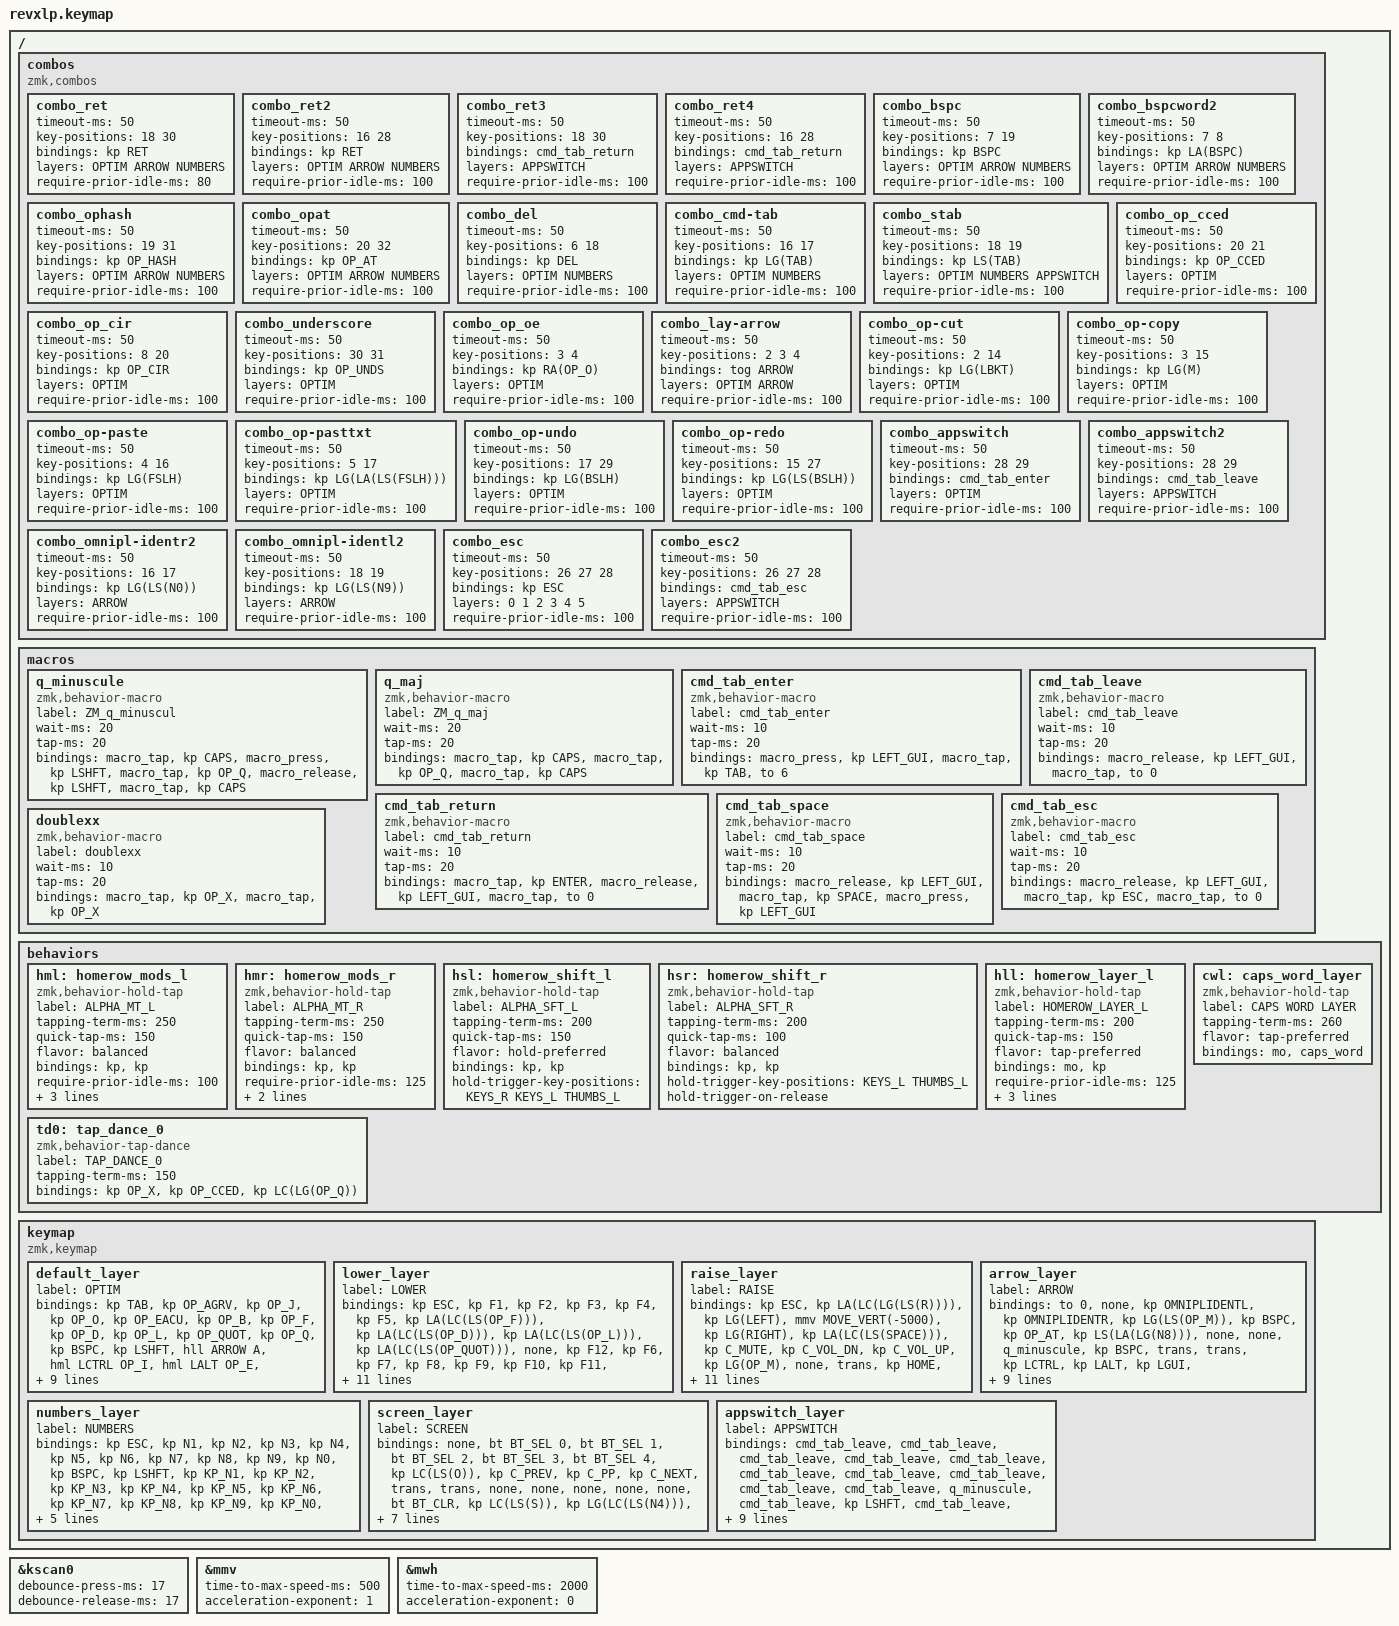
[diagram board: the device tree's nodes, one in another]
/*
 * Copyright (c) 2020 The ZMK Contributors
 *
 * SPDX-License-Identifier: MIT
 */

#include <behaviors.dtsi>
#include <dt-bindings/zmk/keys.h>
#include <dt-bindings/zmk/bt.h>
#include <dt-bindings/zmk/backlight.h>
#include <dt-bindings/zmk/mouse.h>
//#include "keymap_optimot.h"

/*
 * ┌───┬───┬───┬───┬───┬───┬───┬───┬───┬───┬───┬───┬───┬───────┐
 * │ $ │ « │ » │ " │ - │ + │ * │ / │ = │ ( │ ) │ @ │ # │       │
 * ├───┴─┬─┴─┬─┴─┬─┴─┬─┴─┬─┴─┬─┴─┬─┴─┬─┴─┬─┴─┬─┴─┬─┴─┬─┴─┬─────┤
 * │     │ À │ J │ O │ É │ B │ F │ D │ L │ ' │ Q │ X │ Ç │     │
 * ├─────┴┬──┴┬──┴┬──┴┬──┴┬──┴┬──┴┬──┴┬──┴┬──┴┬──┴┬──┴┬──┴┐    │
 * │      │ A │ I │ E │ U │ , │ P │ T │ S │ R │ N │ ^ │ Z │    │
 * ├────┬─┴─┬─┴─┬─┴─┬─┴─┬─┴─┬─┴─┬─┴─┬─┴─┬─┴─┬─┴─┬─┴─┬─┴───┴────┤
 * │    │ K │ Y │ È │ . │ W │   │ G │ C │ M │ H │ V │          │
 * ├────┼───┴┬──┴─┬─┴───┴───┴───┴───┴───┴──┬┴───┼───┴┬────┬────┤
 * │    │    │    │                        │    │    │    │    │
 * └────┴────┴────┴────────────────────────┴────┴────┴────┴────┘
 */
// Row 1
#define OP_DLR  GRAVE // $
#define OP_LDAQ N1    // «
#define OP_RDAQ N2    // »
#define OP_DQUO N3    // "
#define OP_MIN  N4    // -
#define OP_PLUS N5    // +
#define OP_ASTR N6    // *
#define OP_SLSH N7    // /
#define OP_EQL  N8    // =
#define OP_LPRN N9    // (
#define OP_RPRN N0    // )
#define OP_AT   MINUS // @
#define OP_HASH EQUAL // #
// Row 2
#define OP_AGRV Q     // À
#define OP_J    W     // J
#define OP_O    E     // O
#define OP_EACU R     // É
#define OP_B    T     // B
#define OP_F    Y     // F
#define OP_D    U     // D
#define OP_L    I     // L
#define OP_QUOT O     // '
#define OP_Q    P     // Q
#define OP_X    LBKT  // X
#define OP_CCED RBKT  // Ç
// Row 3
#define OP_A    A     // A
#define OP_I    S     // I
#define OP_E    D     // E
#define OP_U    F     // U
#define OP_COMM G     // ,
#define OP_P    H     // P
#define OP_T    J     // T
#define OP_S    K     // S
#define OP_R    L     // R
#define OP_N    SEMI  // N
#define OP_CIR  SQT   // ^
#define OP_Z    BSLH  // Z
// Row 4
#define OP_K    Z     // K
#define OP_Y    X     // Y
#define OP_EGRV C     // È
#define OP_DOT  V     // .
#define OP_W    B     // W
#define OP_G    N     // G
#define OP_C    M     // C
#define OP_M    COMMA // M
#define OP_H    DOT   // H
#define OP_V    FSLH  // V

/* Shifted symbols
 * ┌───┬───┬───┬───┬───┬───┬───┬───┬───┬───┬───┬───┬───┬───────┐
 * │ € │ 1 │ 2 │ 3 │ 4 │ 5 │ 6 │ 7 │ 8 │ 9 │ 0 │ _ │ % │       │
 * ├───┴─┬─┴─┬─┴─┬─┴─┬─┴─┬─┴─┬─┴─┬─┴─┬─┴─┬─┴─┬─┴─┬─┴─┬─┴─┬─────┤
 * │     │   │   │   │   │   │   │   │   │ ? │   │   │   │     │
 * ├─────┴┬──┴┬──┴┬──┴┬──┴┬──┴┬──┴┬──┴┬──┴┬──┴┬──┴┬──┴┬──┴┐    │
 * │      │   │   │   │   │ ; │   │   │   │   │   │ ! │   │    │
 * ├────┬─┴─┬─┴─┬─┴─┬─┴─┬─┴─┬─┴─┬─┴─┬─┴─┬─┴─┬─┴─┬─┴─┬─┴───┴────┤
 * │    │   │   │   │   │ : │   │   │   │   │   │   │          │
 * ├────┼───┴┬──┴─┬─┴───┴───┴───┴───┴───┴──┬┴───┼───┴┬────┬────┤
 * │    │    │    │                        │    │    │    │    │
 * └────┴────┴────┴────────────────────────┴────┴────┴────┴────┘
 */
// Row 1
#define OP_EURO  LS(OP_DLR)  // €
#define OP_1     LS(OP_LDAQ) // 1
#define OP_2     LS(OP_RDAQ) // 2
#define OP_3     LS(OP_DQUO) // 3
#define OP_4     LS(OP_MIN)  // 4
#define OP_5     LS(OP_PLUS) // 5
#define OP_6     LS(OP_ASTR) // 6
#define OP_7     LS(OP_SLSH) // 7
#define OP_8     LS(OP_EQL)  // 8
#define OP_9     LS(OP_LPRN) // 9
#define OP_0     LS(OP_RPRN) // 0
#define OP_UNDS  LS(OP_AT)   // _
#define OP_DEGRE LA(OP_HASH) // º
// Added since this is useful
#define OP_PERC  LS(OP_HASH) // %
// Row 2
#define OP_QUES LS(OP_QUOT)  // ?
// Row 3
#define OP_SCLN LS(OP_COMM)  // ;
// Row 4
#define OP_COLN LS(OP_DOT)   // :
// Row 5
#define OP_NBSP LS(SPACE)   //   (non-breaking space) /!\ Pour la disposition Optimot 1.4 ou 1.5 non altérée, il faut utiler le code LA(SPACE)


//Applications shorcuts
//Omniplan
#define OMNIPLIDENTR LG(LS(N0))
#define OMNIPLIDENTL LG(LS(N9))


#define OPTIM   0
#define LOWER   1
#define RAISE   2
#define ARROW   3
#define NUMBERS 4
#define SCREEN  5
#define APPSWITCH 6

#define CLIPB_HIST LG(LA(OP_P))

/*                KEY POSITIONS

  ╭────────────────────────╮ ╭────────────────────────╮
  │  0   1   2   3   4   5 │ │  6   7   8   9  10  11 │
  │ 12  13  14  15  16  17 │ │ 18  19  20  21  22  23 │
  │ 24  25  26  27  28  29 │ │ 30  31  32  33  34  35 │
  ╰──────────╮  36  37  38 │ │ 39  40  41 ╭───────────╯
             ╰─────────────╯ ╰────────────╯            */

/ {
combos {
    compatible = "zmk,combos";
    combo_ret {
        timeout-ms = <50>;
        key-positions = <18 30>;
        bindings = <&kp RET>;
        layers = <OPTIM ARROW NUMBERS>;
        require-prior-idle-ms = <80>;
    };
    combo_ret2 {
        timeout-ms = <50>;
        key-positions = <16 28>;
        bindings = <&kp RET>;
        layers = <OPTIM ARROW NUMBERS>;
        require-prior-idle-ms = <100>;
    };
    combo_ret3 {
        timeout-ms = <50>; 
        key-positions = <18 30>;
        bindings = <&cmd_tab_return>;
        layers = <APPSWITCH>;
        require-prior-idle-ms = <100>;
    };
    combo_ret4 {
        timeout-ms = <50>;
        key-positions = <16 28>;
        bindings = <&cmd_tab_return>;
        layers = <APPSWITCH>;
        require-prior-idle-ms = <100>;
    };
    combo_bspc {
        timeout-ms = <50>;
        key-positions = <7 19>;
        bindings = <&kp BSPC>;
        layers = <OPTIM ARROW NUMBERS>;
        require-prior-idle-ms = <100>;
    };
    combo_bspcword2 {
        timeout-ms = <50>;
        key-positions = <7 8>;
        bindings = <&kp LA(BSPC)>;
        layers = <OPTIM ARROW NUMBERS>;
        require-prior-idle-ms = <100>;
    };
    combo_ophash {
        timeout-ms = <50>;
        key-positions = <19 31>;
        bindings = <&kp OP_HASH>;
        layers = <OPTIM ARROW NUMBERS>;
        require-prior-idle-ms = <100>;
    };
    combo_opat {
        timeout-ms = <50>;
        key-positions = <20 32>;
        bindings = <&kp OP_AT>;
        layers = <OPTIM ARROW NUMBERS>;
        require-prior-idle-ms = <100>;
    };
    combo_del {
        timeout-ms = <50>;
        key-positions = <6 18>;
        bindings = <&kp DEL>;
        layers = <OPTIM NUMBERS>;
        require-prior-idle-ms = <100>;
    };
    combo_cmd-tab {
        timeout-ms = <50>;
        key-positions = <16 17>;
        bindings = <&kp LG(TAB)>;
        layers = <OPTIM NUMBERS>;
        require-prior-idle-ms = <100>;
    };
    combo_stab {
        timeout-ms = <50>;
        key-positions = <18 19>;
        bindings = <&kp LS(TAB)>;
        layers = <OPTIM NUMBERS APPSWITCH>;
        require-prior-idle-ms = <100>;
    };
    combo_op_cced {
        timeout-ms = <50>;
        key-positions = <20 21>;
        bindings = <&kp OP_CCED>;
        layers = <OPTIM>;
        require-prior-idle-ms = <100>;
    };
    combo_op_cir {
        timeout-ms = <50>;
        key-positions = <8 20>;
        bindings = <&kp OP_CIR>;
        layers = <OPTIM>;
        require-prior-idle-ms = <100>;
    };
    combo_underscore {
        timeout-ms = <50>;
        key-positions = <30 31>;
        bindings = <&kp OP_UNDS>;
        layers = <OPTIM>;
        require-prior-idle-ms = <100>;
    };
    combo_op_oe {
        timeout-ms = <50>;
        key-positions = <3 4>;
        bindings = <&kp RA(OP_O)>;
        layers = <OPTIM>;
        require-prior-idle-ms = <100>;
    };
    combo_lay-arrow {
        timeout-ms = <50>;
        key-positions = <2 3 4>;
        bindings = <&tog ARROW>;
        layers = <OPTIM ARROW>;
        require-prior-idle-ms = <100>;
    };
    combo_op-cut {
        timeout-ms = <50>;
        key-positions = <2 14>;
        bindings = <&kp LG(LBKT)>;
        layers = <OPTIM>;
        require-prior-idle-ms = <100>;
    };
    combo_op-copy {
        timeout-ms = <50>;
        key-positions = <3 15>;
        bindings = <&kp LG(M)>;
        layers = <OPTIM>;
        require-prior-idle-ms = <100>;
    };
    combo_op-paste {
        timeout-ms = <50>;
        key-positions = <4 16>;
        bindings = <&kp LG(FSLH)>;
        layers = <OPTIM>;
        require-prior-idle-ms = <100>;
    };
    combo_op-pasttxt {
        timeout-ms = <50>;
        key-positions = <5 17>;
        bindings = <&kp LG(LA(LS(FSLH)))>;
        layers = <OPTIM>;
        require-prior-idle-ms = <100>;
    };
    combo_op-undo {
        timeout-ms = <50>;
        key-positions = <17 29>;
        bindings = <&kp LG(BSLH)>;
        layers = <OPTIM>;
        require-prior-idle-ms = <100>;
    };
    combo_op-redo {
        timeout-ms = <50>;
        key-positions = <15 27>;
        bindings = <&kp LG(LS(BSLH))>;
        layers = <OPTIM>;
        require-prior-idle-ms = <100>;
    };
    combo_appswitch {
        timeout-ms = <50>;
        key-positions = <28 29>;
        bindings = <&cmd_tab_enter>;
        layers = <OPTIM>;
        require-prior-idle-ms = <100>;
    };
    combo_appswitch2 {
        timeout-ms = <50>;
        key-positions = <28 29>;
        bindings = <&cmd_tab_leave>;
        layers = <APPSWITCH>;
        require-prior-idle-ms = <100>;
    };
    combo_omnipl-identr2 {
        timeout-ms = <50>;
        key-positions = <16 17>;
        bindings = <&kp LG(LS(N0))>;
        layers = <ARROW>;
        require-prior-idle-ms = <100>;
    };// Also works for workflowy WkfyNext
    combo_omnipl-identl2 {
        timeout-ms = <50>;
        key-positions = <18 19>;
        bindings = <&kp LG(LS(N9))>;
        layers = <ARROW>;
        require-prior-idle-ms = <100>;
    };// Also works for workflowy WkfyPrev
    combo_esc {
        timeout-ms = <50>;
        key-positions = <26 27 28>;
        bindings = <&kp ESC>;
        layers = <0 1 2 3 4 5>;
        require-prior-idle-ms = <100>;
    };
    combo_esc2 {
        timeout-ms = <50>;
        key-positions = <26 27 28>;
        bindings = <&cmd_tab_esc>;
        layers = <APPSWITCH>;
        require-prior-idle-ms = <100>;
    };
};
};

&kscan0 { //debounce-period = <17>;
          debounce-press-ms = <17>;
          debounce-release-ms = <17>;
        };

// Mouse specific config
&mmv {    
        time-to-max-speed-ms = <500>;
        acceleration-exponent=<1>;
};
&mwh {    
        time-to-max-speed-ms = <2000>;
        acceleration-exponent=<0>;
};

/ {
    macros {
        q_minuscule: q_minuscule {
            label = "ZM_q_minuscul";
            compatible = "zmk,behavior-macro";
            wait-ms = <20>;
            tap-ms = <20>;
            #binding-cells = <0>;
            bindings
                = <&macro_tap &kp CAPS>
                , <&macro_press &kp LSHFT>
                , <&macro_tap &kp OP_Q>
                , <&macro_release &kp LSHFT>
                , <&macro_tap &kp CAPS>
                ;
        };
        q_maj: q_maj {
            label = "ZM_q_maj";
            compatible = "zmk,behavior-macro";
            wait-ms = <20>;
            tap-ms = <20>;
            #binding-cells = <0>;
            bindings
                = <&macro_tap &kp CAPS>
                , <&macro_tap &kp OP_Q>
                , <&macro_tap &kp CAPS>
                ;
        };
        cmd_tab_enter: cmd_tab_enter {
            label = "cmd_tab_enter";
            compatible = "zmk,behavior-macro";
            #binding-cells = <0>;
            wait-ms = <10>;
            tap-ms = <20>;
            bindings =
                <&macro_press>,
                <&kp LEFT_GUI>,
                <&macro_tap>,
                <&kp TAB &to 6>;
        };
        cmd_tab_leave: cmd_tab_leave {
            label = "cmd_tab_leave";
            compatible = "zmk,behavior-macro";
            #binding-cells = <0>;
            wait-ms = <10>;
            tap-ms = <20>;
            bindings =
                <&macro_release>,
                <&kp LEFT_GUI>,
                <&macro_tap>,
                <&to 0>;
        };
        cmd_tab_return: cmd_tab_return {
            label = "cmd_tab_return";
            compatible = "zmk,behavior-macro";
            #binding-cells = <0>;
            wait-ms = <10>;
            tap-ms = <20>;
            bindings =
                <&macro_tap>,
                <&kp ENTER>,
                <&macro_release>,
                <&kp LEFT_GUI>,
                <&macro_tap>,
                <&to 0>;
        };
        cmd_tab_space: cmd_tab_space {
            label = "cmd_tab_space";
            compatible = "zmk,behavior-macro";
            #binding-cells = <0>;
            wait-ms = <10>;
            tap-ms = <20>;
            bindings =
                <&macro_release>,
                <&kp LEFT_GUI>,
                <&macro_tap>,
                <&kp SPACE>,
                <&macro_press>,
                <&kp LEFT_GUI>;
        };
        cmd_tab_esc: cmd_tab_esc {
            label = "cmd_tab_esc";
            compatible = "zmk,behavior-macro";
            #binding-cells = <0>;
            wait-ms = <10>;
            tap-ms = <20>;
            bindings =
                <&macro_release>,
                <&kp LEFT_GUI>,
                <&macro_tap>,
                <&kp ESC>,
                <&macro_tap>,
                <&to 0>;
        };
        doublexx: doublexx {
            label = "doublexx";
            compatible = "zmk,behavior-macro";
            #binding-cells = <0>;
            wait-ms = <10>;
            tap-ms = <20>;
            bindings =
                <&macro_tap>,
                <&kp OP_X>,
                <&macro_tap>,
                <&kp OP_X>;
        };
    };
};

// Key position groups
#define KEYS_L 0 1 2 3 4 5 12 13 14 15 16 17 24 25 26 27 28 29
#define KEYS_R 6 7 8 9 10 11 18 19 20 21 22 23 30 31 32 33 34 35   //added 0 because I want hold behavior to trigger when fast typing cmd+tab.
#define KEYS_L_SPECIAL 0
#define THUMBS_L 36 37 38
#define THUMB_L_SPECIAL 37
#define THUMBS_R 39 40 41

/*                KEY POSITIONS

  ╭────────────────────────╮ ╭────────────────────────╮
  │  0   1   2   3   4   5 │ │  6   7   8   9  10  11 │
  │ 12  13  14  15  16  17 │ │ 18  19  20  21  22  23 │
  │ 24  25  26  27  28  29 │ │ 30  31  32  33  34  35 │
  ╰───────────╮ 36  37  38 │ │ 39  40  41 ╭───────────╯
              ╰────────────╯ ╰────────────╯            */

/ {
    behaviors {
        hml: homerow_mods_l {
            compatible = "zmk,behavior-hold-tap";
            label = "ALPHA_MT_L";
            #binding-cells = <2>;
            tapping-term-ms = <250>;
            quick-tap-ms = <150>;
            flavor = "balanced";
            bindings = <&kp>, <&kp>;
            //global-quick-tap-ms = <150>;
            require-prior-idle-ms = <100>;
            hold-trigger-key-positions = <KEYS_R KEYS_L_SPECIAL THUMBS_R THUMB_L_SPECIAL>;
            hold-trigger-on-release;
        };
        hmr: homerow_mods_r {
            compatible = "zmk,behavior-hold-tap";
            label = "ALPHA_MT_R";
            #binding-cells = <2>;
            tapping-term-ms = <250>;
            quick-tap-ms = <150>;
            flavor = "balanced";
            bindings = <&kp>, <&kp>;
            //global-quick-tap-ms = <150>;
            require-prior-idle-ms = <125>;
            hold-trigger-key-positions = <KEYS_L THUMBS_L>;
            hold-trigger-on-release;
        };
        hsl: homerow_shift_l {
            compatible = "zmk,behavior-hold-tap";
            label = "ALPHA_SFT_L";
            #binding-cells = <2>;
            tapping-term-ms = <200>;
            quick-tap-ms = <150>;
            flavor = "hold-preferred";
            bindings = <&kp>, <&kp>;
            hold-trigger-key-positions = <KEYS_R KEYS_L THUMBS_L>;
            //hold-trigger-on-release;
        };
        hsr: homerow_shift_r {
            compatible = "zmk,behavior-hold-tap";
            label = "ALPHA_SFT_R";
            #binding-cells = <2>;
            tapping-term-ms = <200>;
            quick-tap-ms = <100>; //trying to see if quick right hm shift with X works better with 100 instead of 150. Note : since I moved X from inner left thumb key, this change might not be a good idea anymore.
            flavor = "balanced";
            bindings = <&kp>, <&kp>;
            hold-trigger-key-positions = <KEYS_L THUMBS_L>;
            hold-trigger-on-release;
        };
        hll: homerow_layer_l {
            compatible = "zmk,behavior-hold-tap";
            label = "HOMEROW_LAYER_L";
            #binding-cells = <2>;
            tapping-term-ms = <200>; // switched from 300 to 200, getting too much "af" instead of "@" (layer not triggered)
            quick-tap-ms = <150>; //trying to see what gives with 0 instead of 150 => not kept.
            flavor = "tap-preferred";
            bindings = <&mo>, <&kp>;
            require-prior-idle-ms = <125>;
            hold-trigger-key-positions = <KEYS_R THUMBS_L THUMBS_R>;
            hold-trigger-on-release;
        };
        cwl: caps_word_layer {
            compatible = "zmk,behavior-hold-tap";
            label = "CAPS WORD LAYER";
            #binding-cells = <2>;
            tapping-term-ms = <260>;
            //quick-tap-ms = <0>;
            flavor = "tap-preferred";
            bindings = <&mo>, <&caps_word>;
        };
        td0: tap_dance_0 {
            compatible = "zmk,behavior-tap-dance";
            label = "TAP_DANCE_0";
            #binding-cells = <0>;
            tapping-term-ms = <150>;
            bindings = <&kp OP_X>, <&kp OP_CCED>, <&kp LC(LG(OP_Q))>;
        };
    };

/*                KEY POSITIONS

  ╭────────────────────────╮ ╭────────────────────────╮
  │  0   1   2   3   4   5 │ │  6   7   8   9  10  11 │
  │ 12  13  14  15  16  17 │ │ 18  19  20  21  22  23 │
  │ 24  25  26  27  28  29 │ │ 30  31  32  33  34  35 │
  ╰───────────╮ 36  37  38 │ │ 39  40  41 ╭───────────╯
              ╰────────────╯ ╰────────────╯            */

    keymap {
        compatible = "zmk,keymap";

        default_layer {
        label = "OPTIM";
// ---------------------------------------------------------------------------------------------------------------------
// |  TAB   |  À  |  J  |    O     |   É   |     B     |                   |  ^      |  V     |  D    |  L   |   J   | BKSPC |
// | LSHFT  |  A  |  I  |    E     |   U   |     ,     |                   |  C      |  T     |  S    |  R   |   N   |   M   |
// |MISSCTRL|  K  |  Y  |    È     |   .   |     W     |                   |  '      |  Q     |  G    |  H   |   F   |   Ç   |
//                     | LOWER /   |   X / | CMD/ENTER |                   | NUMBER/ | RAISE/ | RC+SPC|
//                     | CLIPB HIST| LSHFT |                             | SPACE   |  W     | 
            bindings = <
&kp TAB   &kp OP_AGRV  &kp OP_J        &kp OP_O             &kp OP_EACU    &kp OP_B                     &kp OP_F       &kp OP_D          &kp OP_L       &kp OP_QUOT     &kp OP_Q &kp BSPC
&kp LSHFT &hll ARROW A &hml LCTRL OP_I &hml LALT OP_E       &hml LGUI OP_U &kp OP_COMM                  &kp OP_P       &hmr RGUI OP_T    &hmr RALT OP_S &hmr RCTRL OP_R &kp OP_N &kp OP_CIR
&kp F10   &kp OP_K     &kp OP_Y        &kp OP_EGRV          &kp OP_DOT     &hll SCREEN OP_W             &kp OP_G       &hsr RSHFT OP_C   &kp OP_M       &kp OP_H        &kp OP_V &kp OP_CCED
                                       &lt LOWER CLIPB_HIST &hsl LSHFT TAB &mt LGUI SPACE               &lt NUMBERS SPACE &lt RAISE OP_Z  &td0 

            //code pour utiler Caps_Word : &cwl RAISE 0 (pas adapté à Optimot au 04/07/2022; les keycodes Qwerty sont pris en compte, et même si on peut
            // faire en sorte que certains keycodes ne désactivent pas Caps, je ne vois pas pour le moment comment faire pour que des keycodes
            // qwerty de lettres et qui sont par exemple , ou . en optimot puissent désactiver CAPS au lieu de le laisser actif).
            // Update : PeteJohansson m'a recommandé d'ouvrir une issue sur le github avec mes propositions. À faire éventuellement quand j'aurai du temps.
            >;
        };

        lower_layer {
        label = "LOWER";
// ----------------------------------------------------------------------------------------------------------------
// | ESC   |  F1 |  F2 |  F3  |  F4      |  F5  |                   |NextDisplay|Maximize Window|   8   |   9  |    0  |  F12  |
// |   F6  |  F7 |  F8 |  F9  |  F10     |  F11 |                   |  ^   |  &    |  *    |  (   |   )   |   |   |
// |       |  =  |  -  |  +   |DoNotDist |  F12 |                   |  [   |  ]    |  ;    |  :   |   \   |       |
//               |     |      |          |      |                   |      |       |       |      |
            bindings = <                       
&kp ESC &kp F1 &kp F2 &kp F3 &kp F4      &kp F5               &kp LA(LC(LS(OP_F)))     &kp LA(LC(LS(OP_D)))     &kp LA(LC(LS(OP_L)))      &kp LA(LC(LS(OP_QUOT))) &none                 &kp F12
&kp F6  &kp F7 &kp F8 &kp F9 &kp F10     &kp F11              &kp LA(LC(LS(OP_P)))     &kp LA(LC(LS(LEFT)))     &kp LA(LC(LS(UP)))        &kp LA(LC(LS(DOWN)))    &kp LA(LC(LS(RIGHT))) &kp LS(LA(LC(LG(OP_G))))
&kp F3  &none  &none  &none  &kp LG(F12) &kp F12              &kp LA(LC(LS(OP_G)))     &kp LC(LG(OP_Q))         &kp LA(LC(LS(OP_M)))      &kp LA(LC(LS(OP_H)))    &none                 &kp LS(LA(LC(LG(OP_D))))
                      &trans &trans      &trans               &kp LG(LA(LC(LS(LEFT)))) &kp LG(LA(LC(LS(DOWN)))) &kp LG(LA(LC(LS(RIGHT))))      
            >;
        };

        raise_layer {
        label = "RAISE";
// -----------------------------------------------------------------------------------------------------------------------------------------------------------
// |                     |NewOmniFocTaskFromTxt| HOME       | MouseUP      |  END       |Spotlight|             |      |      |       |      |       |       |
// |NewOmniFocTaskFromTxt| INS                 | Mouseleft  | MouseDwn     | MouseRght  |      |                | PGUP |      |   ^   |      |       | OutlkNewMainWindow|
// |AppsForceQuit        | FileMailOutlook     | HookCpyLk  | HookCpyMDLk  | HookToLink |EMOJI|                |      |      |       |      |       |       |
//                                                          |              |            | Hook |                |      |      |       |
            bindings = <    
&kp ESC               &kp LA(LC(LG(LS(R)))) &kp LG(LEFT)          &mmv MOVE_VERT(-5000) &kp LG(RIGHT)         &kp LA(LC(LS(SPACE)))               &kp C_MUTE &kp C_VOL_DN        &kp C_VOL_UP          &kp LG(OP_M)        &none                &trans
&kp HOME              &kp RA(RG(G))         &mmv MOVE_HOR(-5000)  &mmv MOVE_VERT(5000)  &mmv MOVE_HOR(5000)   &kp END                             &kp PG_UP  &mkp LCLK           &mkp RCLK             &kp LG(LS(OP_M))    &none                &kp LA(LG(LS(OP_N)))
&kp LA(LG(ESC))       &kp LC(D)             &kp LG(KP_N0)         &kp LG(MINUS)         &kp  LG(EQUAL)        &kp LC(LG(SPACE))                   &kp PG_DN  &mwh SCROLL_HOR(15) &mwh SCROLL_VERT(-15) &mwh SCROLL_VERT(15) &mwh SCROLL_HOR(-15) &none
                                                                  &trans                &trans                &trans                              &trans     &trans              &trans  
            >;
        };

        arrow_layer {
        label = "ARROW";
// ----------------------------------------------------------------------------------------------------------------------------------------------------------------
// | TO 0  | none| OMNIPLIDENTR     | OMNIPLIDENTL         | WkfyMirror  |  BSPC     |                   |  @   |  Rycst-MenuCmd  |  none  |  none   |  q    |      |
// | Trans |Trans|          |              |             |  1PassWD  |                   |  #   |  Left           |  UP    |  Down   | Right   |  None |
// | RESET |     |HookCpyLk | HookCpyMDLk  | HookToLink  |   Hook    |                   |  ??ê?? |  $/€          |PGUP|PGDWN|TxTXSearch|TxTXDisable|
//                          |              |   LSHFT     |CMD/return |                   |  SPC |WkfyPrev         |WkfyNext|
            bindings = <
&to 0       &none     &kp OMNIPLIDENTL      &kp OMNIPLIDENTR      &kp LG(LS(OP_M))      &kp BSPC                       &kp OP_AT            &kp LS(LA(LG(N8))) &none         &none      &q_minuscule         &kp BSPC
&trans      &trans    &kp LCTRL             &kp LALT              &kp LGUI              &kp LS(LA(LG(OP_P)))           &kp OP_HASH          &kp LEFT           &kp UP        &kp DOWN   &kp RIGHT            &q_maj
&bootloader &none     &kp LG(LC(LA(SPACE))) &kp LS(LA(LG(SPACE))) &kp LC(LS(LG(SPACE))) &kp LG(LS(SPACE))              &kp NON_US_BACKSLASH &kp OP_DLR         &kp PG_UP     &kp PG_DN  &kp RG(LS(LA(OP_F))) &kp RA(RC(RG(OP_T)))
                                            &trans                &trans                &trans                         &hmr RSHFT SPACE     &kp HOME           &kp END
            >;
        };

        numbers_layer {
        label = "NUMBERS";
// ------------------------------------------------------------------------------------------------------------
// | TAB   |  «° |  °» |  "   |  -   |  +      |                   |  *   |  /    |  =    |  (   |   )   |  BSPC |
// | LSHFT |   1 |   2 |   3  |   4  |   5     |                   |   6  |   7   |   8   |   9  |    0  |   @/_ |
// | F10   | ??ê?? |  ;  |  :   |  .   |   &     |                   |  ,   |   No  |   No  |   H   |   No  |   #/% |
//                     | LCTRL| LALT |CMD/space|                   | togg | RCTRL | RALT  |
            bindings = <            
&kp ESC   &kp N1     &kp N2      &kp N3    &kp N4    &kp N5                    &kp N6      &kp N7      &kp N8    &kp N9    &kp N0    &kp BSPC
&kp LSHFT &kp KP_N1  &kp KP_N2   &kp KP_N3 &kp KP_N4 &kp KP_N5                 &kp KP_N6   &kp KP_N7   &kp KP_N8 &kp KP_N9 &kp KP_N0 &kp OP_AT
&kp CAPS  &kp OP_DLR &kp OP_SCLN &kp OP_COLN &trans  &kp LA(OP_T)              &kp OP_COMM &kp OP_HASH &kp OP_AT &trans    &none     &kp OP_HASH
                                &kp RALT &kp LSHFT  &mt LGUI SPACE            &trans      &kp LALT   &kp RCTRL
            >;
        };

         screen_layer {
         label = "SCREEN";
// TODO: update layer description
// ------------------------------------------------------------------------------------------------------------
// |     |     |     |     |     |     |                   |            |     |     |     |     |     |
// |     |     |     |     |     |     |                   |            |     |     |     |     |     |
// |     |     |     |     |     |     |                   |MuteMicTeams|     |     |     |     |     |
//                   |     |     |     |                   |            |     |     |

            bindings = <
&none &bt BT_SEL 0 &bt BT_SEL 1 &bt BT_SEL 2 &bt BT_SEL 3 &bt BT_SEL 4                 &kp LC(LS(O))    &kp C_PREV         &kp C_PP       &kp C_NEXT         &trans         &trans
&none &none        &none        &none        &none        &bt BT_CLR                   &kp LC(LS(S))    &kp LG(LC(LS(N4))) &kp LG(LS(N4)) &kp LG(LC(LS(N3))) &kp LG(LS(N3)) &trans
&none &none        &none        &none        &none        &trans                       &kp LG(LS(OP_M)) &kp LG(LS(N9))     &kp RG(RS(UP)) &kp RG(RS(DOWN))   &kp LG(LS(N0)) &bl BL_CYCLE
                                &none        &none        &bl BL_TOG                   &kp SPACE        &bl BL_DEC         &bl BL_INC   
            >;
        };

         appswitch_layer {
         label = "APPSWITCH";
// TODO: update table
// ------------------------------------------------------------------------------------------------------------
// |     |     |     |     |     |     |                  |      |       |       |      |       |       |
// |     |     |     |     |     |     |                  |      |       |       |      |       |       |
// |     |     |     |     |     |     |                  |      |       |       |      |       |       |
//                   |     |     |     |                  |      |       |       |      |       |       |
            bindings = <
&cmd_tab_leave &cmd_tab_leave &cmd_tab_leave &cmd_tab_leave &cmd_tab_leave &cmd_tab_leave                 &cmd_tab_leave &cmd_tab_leave &cmd_tab_leave &cmd_tab_leave &q_minuscule   &cmd_tab_leave
&kp LSHFT      &cmd_tab_leave &cmd_tab_leave &cmd_tab_leave &cmd_tab_leave &cmd_tab_leave                 &cmd_tab_leave &kp LEFT       &kp UP         &kp DOWN       &kp RIGHT      &cmd_tab_leave
&cmd_tab_leave &cmd_tab_leave &cmd_tab_leave &cmd_tab_leave &cmd_tab_leave &cmd_tab_leave                 &cmd_tab_leave &cmd_tab_leave &cmd_tab_leave &cmd_tab_leave &cmd_tab_leave &cmd_tab_leave
                                             &cmd_tab_leave &kp TAB        &cmd_tab_space                 &cmd_tab_space &cmd_tab_leave &cmd_tab_leave   
            >;
        };
   };
};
